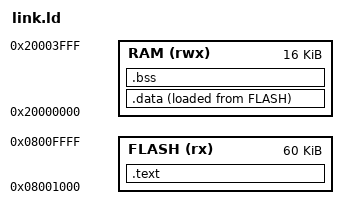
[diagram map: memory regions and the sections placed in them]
ENTRY(Reset_Handler)
MEMORY
{
  FLASH (rx) : ORIGIN = 0x08001000, LENGTH = 60K
  RAM  (rwx) : ORIGIN = 0x20000000, LENGTH = 16K
}
SECTIONS
{
  .text :
  {
    KEEP(*(.vectors))
    *(.text*)
    *(.rodata*)
    . = ALIGN(4);
  } > FLASH

  .data :
  {
    . = ALIGN(4);
    _sdata = .;
    *(.data*)
    . = ALIGN(4);
    _edata = .;
  } > RAM AT > FLASH
  _sidata = LOADADDR(.data);

  .bss :
  {
    . = ALIGN(4);
    _sbss = .;
    *(.bss*)
    *(COMMON)
    . = ALIGN(4);
    _ebss = .;
  } > RAM
}
